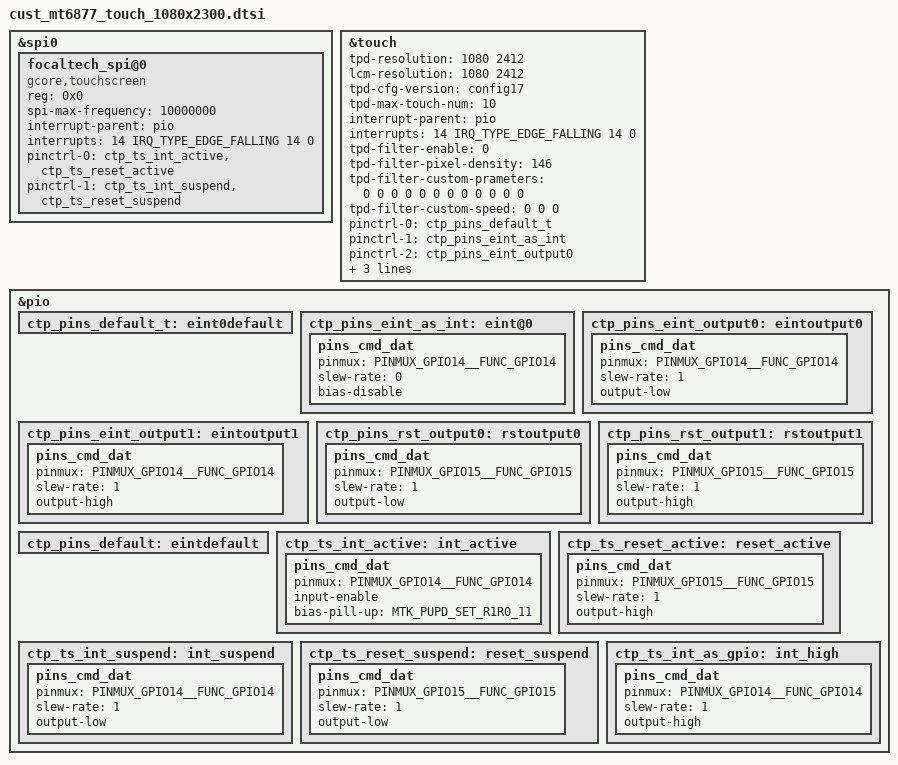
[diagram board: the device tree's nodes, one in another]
// SPDX-License-Identifier: GPL-2.0
/*
 * Copyright (c) 2021 MediaTek Inc.
 */

/* TOUCH start */


&spi0 {
	status = "ok";
	focaltech_spi@0 {
		compatible = "gcore,touchscreen";
		reg = <0x0>;
		spi-max-frequency = <10000000>;
		interrupt-parent = <&pio>;

		interrupts = <14 IRQ_TYPE_EDGE_FALLING 14 0>;
		pinctrl-names = "pmx_ts_active","pmx_ts_suspend";
		pinctrl-0 = <&ctp_ts_int_active &ctp_ts_reset_active>;
		pinctrl-1 = <&ctp_ts_int_suspend &ctp_ts_reset_suspend>;

	};

};


&touch {
	tpd-resolution = <1080 2412>;
	lcm-resolution = <1080 2412>;
	tpd-cfg-version = "config17";
	tpd-max-touch-num = <10>;
	interrupt-parent = <&pio>;
	interrupts = <14 IRQ_TYPE_EDGE_FALLING 14 0>;

	tpd-filter-enable = <0>;
	tpd-filter-pixel-density = <146>;
	tpd-filter-custom-prameters = <0 0 0 0 0 0 0 0 0 0 0 0>;
	tpd-filter-custom-speed = <0 0 0>;
	
	pinctrl-names = "default", "state_eint_as_int", "state_eint_output0",
		"state_eint_output1", "state_rst_output0", "state_rst_output1";
	pinctrl-0 = <&ctp_pins_default_t>;
	pinctrl-1 = <&ctp_pins_eint_as_int>;
	pinctrl-2 = <&ctp_pins_eint_output0>;
	pinctrl-3 = <&ctp_pins_eint_output1>;
	pinctrl-4 = <&ctp_pins_rst_output0>;
	pinctrl-5 = <&ctp_pins_rst_output1>;
	status = "okay";
};

&pio {
	ctp_pins_default_t: eint0default {
	};
	ctp_pins_eint_as_int: eint@0 {
		pins_cmd_dat {
			pinmux = <PINMUX_GPIO14__FUNC_GPIO14>;
			slew-rate = <0>;
			bias-disable;
		};
	};
	ctp_pins_eint_output0: eintoutput0 {
		pins_cmd_dat {
			pinmux = <PINMUX_GPIO14__FUNC_GPIO14>;
			slew-rate = <1>;
			output-low;
		};
	};
	ctp_pins_eint_output1: eintoutput1 {
		pins_cmd_dat {
			pinmux = <PINMUX_GPIO14__FUNC_GPIO14>;
			slew-rate = <1>;
			output-high;
		};
	};
	ctp_pins_rst_output0: rstoutput0 {
		pins_cmd_dat {
			pinmux = <PINMUX_GPIO15__FUNC_GPIO15>;
			slew-rate = <1>;
			output-low;
		};
	};
	ctp_pins_rst_output1: rstoutput1 {
		pins_cmd_dat {
			pinmux = <PINMUX_GPIO15__FUNC_GPIO15>;
			slew-rate = <1>;
			output-high;
		};
	};
};

&pio {
	ctp_pins_default: eintdefault {
	};
	ctp_ts_int_active: int_active {
		pins_cmd_dat {
			pinmux = <PINMUX_GPIO14__FUNC_GPIO14>;
			input-enable;
			bias-pill-up = <MTK_PUPD_SET_R1R0_11>;
		};
	};
	ctp_ts_reset_active: reset_active {
		pins_cmd_dat {
			pinmux = <PINMUX_GPIO15__FUNC_GPIO15>;
			slew-rate = <1>;
			output-high;
		};
	};
	ctp_ts_int_suspend: int_suspend {
		pins_cmd_dat {
			pinmux = <PINMUX_GPIO14__FUNC_GPIO14>;
			slew-rate = <1>;
			output-low;
		};
	};
	ctp_ts_reset_suspend: reset_suspend {
		pins_cmd_dat {
			pinmux = <PINMUX_GPIO15__FUNC_GPIO15>;
			slew-rate = <1>;
			output-low;
		};
	};
	ctp_ts_int_as_gpio: int_high {
		pins_cmd_dat {
			pinmux = <PINMUX_GPIO14__FUNC_GPIO14>;
			slew-rate = <1>;
			output-high;
		};
	};
};
/* TOUCH end */
